# TZ10xx register map
File version: 0.1g
Registers are 32-bit, read-write, reset 0x0 unless marked. A register's access mark holds for its fields unless they carry their own. Offsets are from the block's base; [hi:lo] are bit positions; {n}, {i} and the like mark numbered series.

## spic
Base 0x40004000
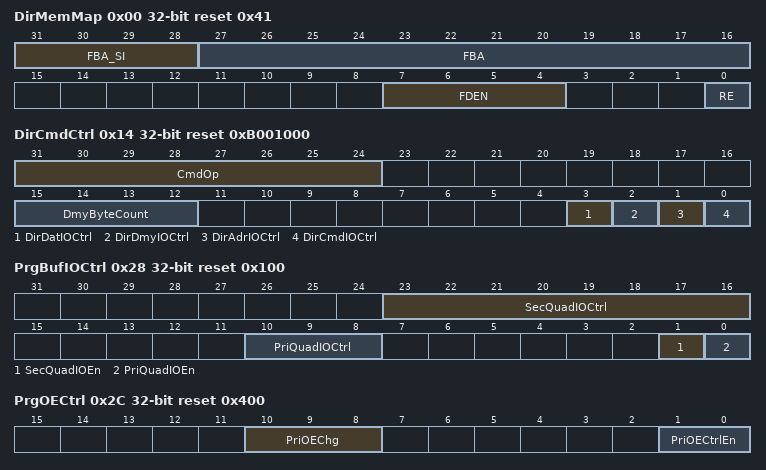
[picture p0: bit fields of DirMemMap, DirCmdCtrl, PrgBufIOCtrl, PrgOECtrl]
0x00 DirMemMap reset 0x41 — Direct access address mapping register
  [31:28] FBA_SI ro — Indicates [31:28] of the base address for mapping Flash. This value is determined with an input signal. It is fixed at 0 in this product.
  [27:16] FBA — Specifies [27:16] of the base address for mapping Flash. This value needs to be aligned by a value specified with the Flash capacity. If it is not aligned, operation is not guaranteed.
  [7:4] FDEN — Flash capacity 0x0:64KB, 0x1:128KB, 0x2:256KB, 0x3:512KB, 0x4:1MB, 0x5:2MB, 0x6:4MB, 0x7:8MB, 0x8:16MB Any values other than the above are reserved.
  [0] RE — Read Enable
0x10 DirAccCtrl — Direct access control register
  [0] PollWIP — Polling Status WIP 0: Polling function OFF 1: Polling function ON
0x14 DirCmdCtrl reset 0xB001000 — Direct access command control register
  [31:24] CmdOp — SPI Command Opcode Sets a command to be sent to SPI Flash through direct access. The initial value is FastRead(0x0B). If QuadAccess is selected with BootMode(MCU_BOOTMODE2), the initial value is FastReadQuadIO(0xEB).
  [15:12] DmyByteCount — Dummy Byte Count Specifies the data amount of a dummy cycle in byte units. If QuadAccess is selected with BootMode(MCU_BOOTMODE2), the initial value is 0x3.
  [3] DirDatIOCtrl — SPI Data I/O Control Select the data transfer operations. Change to match the instruction that has been set to [DirCmdCtrl].CmdOp. 0: Single 1: Quad If QuadAccess is selected with BootMode(MCU_BOOTMODE2), the initial value is 0x1.
  [2] DirDmyIOCtrl — SPI Dummy I/O Control Select the dummy cycle data transfer operations. Change to match the instruction that has been set to [DirCmdCtrl].CmdOp. 0: Single 1: Quad If QuadAccess is selected with BootMode(MCU_BOOTMODE2), the initial value is 0x1.
  [1] DirAdrIOCtrl — SPI Address I/O Control Select the address transfer operations. Change to match the instruction that has been set to [DirCmdCtrl].CmdOp. 0: Single 1: Quad If QuadAccess is selected with BootMode(MCU_BOOTMODE2), the initial value is 0x1.
  [0] DirCmdIOCtrl — SPI Command I/O Control Select the Command transfer operations. Change to match the instruction that has been set to [DirCmdCtrl].CmdOp. 0: Single 1: Quad
0x20 PrgSRAMAddr reset 0x10000000 — SRAM transfer address register
  [31:0] SRAMAddr — Specifies the SRAM address of the transfer source (destination) used for transfer between Flash and SRAM. The initial value is set for the sram T0 area (0x10000000).
0x24 PrgSRAMTrSize reset 0x40000 — SRAM transfer size register
  [19:0] TrSize — Sets the transfer size between Flash and SRAM. At reading, the upper limit value for transfer is 256KB(0x40000). At writing, since SpiFlashMemory write occurs at every 256Byte boundary, set "SpiFlash transfer address setting [7:0] + transfer size" so that it does not exceed 256 bytes. If Remap1 Mode is selected with BootMode(MCU_BOOTMODE1), the initial value is 224KB(0x38000).
0x28 PrgBufIOCtrl reset 0x100 — Program register access IO control register
  [23:16] SecQuadIOCtrl — Specifies the Quad control timing of SecondaryBuffer and SRAM transfer. Use the initial value(0x00) for this setting.
  [10:8] PriQuadIOCtrl — Specifies Quad control of PrimaryBuffer (0-7 specification) Quad processing is performed from data in the specified buffer location.
  [1] SecQuadIOEn — Secondary Buffer/SRAM Quad output Enable 0: Single 1: Quad If 1 is set, Secondary Buffer and SRAM data is transferred with Quad. If QuadAccess is selected with BootMode(MCU_BOOTMODE2), the initial value is 0x1.
  [0] PriQuadIOEn — Primary Buffer Quad output Enable 0: Single 1: Quad If 1 is set, Primary Buffer data is transferred with Quad. The location of data from which Quad transfer starts is set with PriQuadIOCtrl. If QuadAccess is selected with BootMode(MCU_BOOTMODE2), the initial value is 0x1.
0x2C PrgOECtrl reset 0x400 — Program register access OutEnable control register
  [10:8] PriOEChg — Specifies the data location in which OutEnable is switched during PrimaryBuffer data transmission. During Quad transfer, specify the location of PrimaryBuffer in which the first 1 byte of dummy cycle data is stored. Specify "4" if that byte is stored in [PrimaryBuffer1].PriBuf4.
  [1:0] PriOECtrlEn — To switch the command, address, dummy cycle data transmission to the read data reception, switches enable/disable of the function that controls output enable. 0: Disables the function. 1: Switches enable/disable in the buffer data output timing specified with PriOEChg. 2, 3: Setting prohibited. If QuadAccess is selected with BootMode(MCU_BOOTMODE2), the initial value is 0x1.
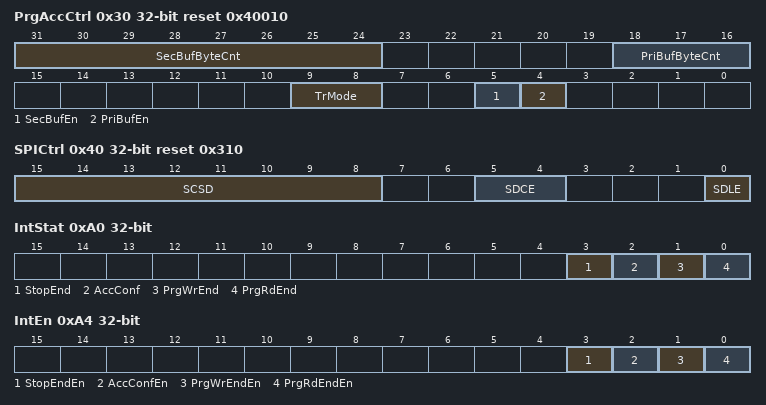
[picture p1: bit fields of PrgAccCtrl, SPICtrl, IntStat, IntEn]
0x30 PrgAccCtrl reset 0x40010 — Program register access control register
  [31:24] SecBufByteCnt — Secondary Buffer Data Byte Count Specifies the amount of SecondaryBuffer to be used. Set a value of "number of bytes to be used - 1".
  [18:16] PriBufByteCnt — Primary Buffer Data Byte Count Specifies the amount of PrimaryBuffer to be used. Set a value of "number of bytes to be used - 1". If QuadAccess is selected with BootMode(MCU_BOOTMODE2), the initial value is 0x6.
  [9:8] TrMode — Specifies the transfer direction of program register access. 0: Flash Memory -> SRAM transfer (Flash Read) 1: SRAM transfer -> Flash Memory (Flash Write) 2: Flash Memory -> internal buffer (Flash Read) 3: Internal buffer -> Flash Memory (Flash Write) When data transfer is not accompanied, if only command transmission is done to SPI Flash, use the setting of "Internal buffer ->FlashMemory". If a command is issued which receives information such as status from FlashMemory, use the setting of "FlashMemory->internal buffer".
  [5] SecBufEn — Secondary Buffer Enable Switches use/non-use of Secondary Buffer.
  [4] PriBufEn ro — Primary Buffer Enable PrimaryBuffer is always set to ON.
0x34 PrgStart — Program register access start register
  [0] Start — Indicates the start of program register access. 0: Disables writing. 1: Starts transfer by writing. At reading, 0 is read from this register. If 1 is set while PrgAccBusy of the [status] register is 1, no operation is guaranteed.
0x40 SPICtrl reset 0x310 — SPI transfer control register
  [15:8] SCSD — Specifies the chip select signal (CS_N) deassert period with the number of cycles of SPI_CLK. As the initial value, 3 cycles is set which satisfies winbond tSHSL2(50ns) for SPI_CLK maximum frequency 48MHz.
  [5:4] SDCE — SPI Data Capture Edge 0: 1st posedge 1: 1st negedge 2,3: not used
  [0] SDLE — SPI Data Launch Edge 0: negedge 1: posedge
0x50 CodeStatus — Code status at address of 0x000000
  [0] NoCodeFlag — Indicates that there is no data of address 0x000000 when checked at boot sequence. 0:Data is not 0xffffffff. 1:Data 0xffffffff. If 1 is written, the value is cleared. 0 write disabled.
0xA0 IntStat — Interrupt status
  [3] StopEnd — Indicates that the SPI transfer suspension processing by the SPI transfer suspension register setting has been completed. If 1 is written, the value is cleared. (0 writing disabled)
  [2] AccConf — Indicates the conflict detection between direct access and program register access. If 1 is written, the value is cleared. (0 writing disabled)
  [1] PrgWrEnd — Indicates that write transfer has been completed for program register access. If 1 is written, the value is cleared. (0 writing disabled)
  [0] PrgRdEnd — Indicates that read transfer has been completed for program register access. If 1 is written, the value is cleared. (0 writing disabled)
0xA4 IntEn — Interrupt factor enable
  [3] StopEndEn — Switches enable/disable of interrupt output caused by SPI transfer suspension completion. 0: Disable 1: Enable If Disable is set, no interrupt is output at factor generation. However, this setting is applied to the interrupt status ([IntStat]).
  [2] AccConfEn — Switches enable/disable of interrupt output caused by the factor of direct access/program register access conflict. 0: Disable 1: Enable If Disable is set, no interrupt is output at factor generation. However, this setting is applied to the interrupt status ([IntStat]).
  [1] PrgWrEndEn — Switches enable/disable of output of the program register access write transfer completion. 0: Disable 1: Enable If Disable is set, no interrupt is output at factor generation. However, this setting is applied to the interrupt status ([IntStat]).
  [0] PrgRdEndEn — Switches enable/disable of output of the program register access read transfer completion. 0: Disable 1: Enable If Disable is set, no interrupt is output at factor generation. However, this setting is applied to the interrupt status ([IntStat]).
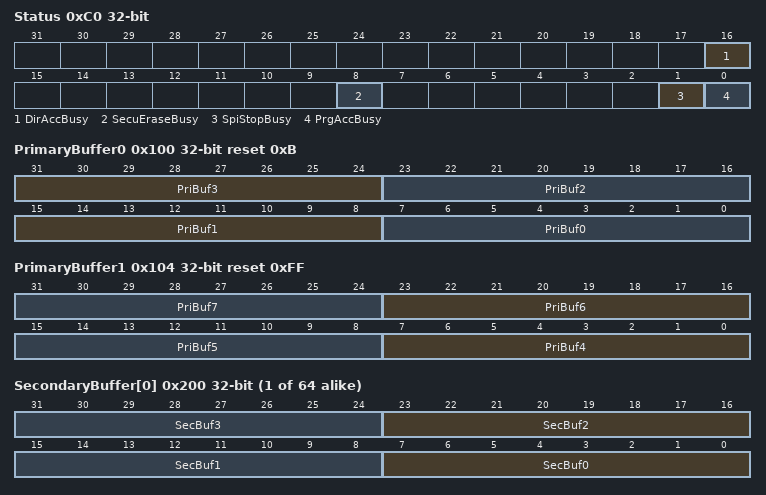
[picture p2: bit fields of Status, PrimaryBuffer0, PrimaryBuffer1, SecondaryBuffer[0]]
0xC0 Status ro — Internal status
  [16] DirAccBusy — Indicates that direct access is in progress.
  [8] SecuEraseBusy — Indicates that Flash Erase by PMU is in progress.
  [1] SpiStopBusy — Indicates that Spi suspension processing is in progress.
  [0] PrgAccBusy — Indicates that program register access is in progress.
0xF0 SpiStop — SPI transfer suspension register
  [0] Stop — SPI transfer suspension indication If 1 is set in this register and SPI transfer is in progress, clock supply to SPI Flash is stopped and CS_N deassert processing occurs. At reading, a written value is read. If this value is 1, neither direct access nor program register access is performed even if access is newly done. Note: If an instruction is set in Flash, do not use this function because it would not be fetched normally. Moreover, if the suspension function is used, transfer is stopped midway and no data is guaranteed. (During direct access, Ready is returned midway to complete bus transfer. However, the returned data becomes invalid.)
0x100 PrimaryBuffer0 reset 0xB — PrimaryBuffer Buffer for storing commands, addresses, dummy cycle data for program register access
  [31:24] PriBuf3 — PrimaryBuffer3
  [23:16] PriBuf2 — PrimaryBuffer2
  [15:8] PriBuf1 — PrimaryBuffer1
  [7:0] PriBuf0 — PrimaryBuffer0 Set the command usually. The initial value is FastRead(0x0B). However, if QuadAccess is selected with BootMode(MCU_BOOTMODE2), the initial value is FastReadQuadIO(0xEB).
0x104 PrimaryBuffer1 reset 0xFF — PrimaryBuffer Buffer for storing commands, addresses, dummy cycle data for program register access
  [8n-25:8n-32] PriBuf{n} (n=4..7) — PrimaryBuffer{n}
{0x200+4i} SecondaryBuffer[{i}] (i=0..63) — SecondaryBuffer Buffer for storing data to be transferred for program register access This buffer has the area of 256Byte in total.
  [8n+7:8n] SecBuf{n} (n=0..3)
